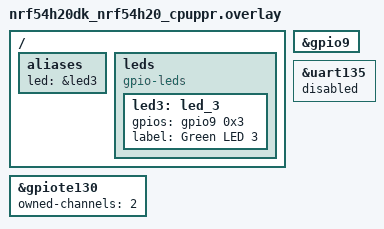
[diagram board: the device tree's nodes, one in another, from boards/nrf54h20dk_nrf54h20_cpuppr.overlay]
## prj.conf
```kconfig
CONFIG_GPIO=y

CONFIG_NCS_BOOT_BANNER=n
CONFIG_BOOT_BANNER=n
CONFIG_ASSERT=y

CONFIG_PRINTK=n
CONFIG_LOG=n
CONFIG_CONSOLE=n
CONFIG_UART_CONSOLE=n
CONFIG_SERIAL=n
```

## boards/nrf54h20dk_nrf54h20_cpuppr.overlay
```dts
/*
 * Copyright (c) 2026 Nordic Semiconductor ASA
 *
 * SPDX-License-Identifier: LicenseRef-Nordic-5-Clause
 */

/ {
	aliases {
		led = &led3;
	};

	leds {
		compatible = "gpio-leds";

		led3: led_3 {
			gpios = <&gpio9 0x3 0x0>;
			label = "Green LED 3";
		};
	};
};

&gpio9 {
	status = "okay";
};

&gpiote130 {
	status = "okay";
	owned-channels = <2>;
};

/* UART135 is owned by Radio core. */
&uart135 {
	status = "disabled";
};
```

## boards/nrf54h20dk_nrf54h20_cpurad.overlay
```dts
/*
 * Copyright (c) 2024 Nordic Semiconductor ASA
 *
 * SPDX-License-Identifier: LicenseRef-Nordic-5-Clause
 */

/ {
	aliases {
		led = &led1;
	};

	leds {
		compatible = "gpio-leds";

		led1: led_1 {
			gpios = <&gpio9 1 GPIO_ACTIVE_HIGH>;
			label = "Green LED 1";
		};
	};
};

&gpio9 {
	status = "okay";
};

&gpiote130 {
	status = "okay";
};
```

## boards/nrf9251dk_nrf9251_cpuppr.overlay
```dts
/*
 * Copyright (c) 2026 Nordic Semiconductor ASA
 *
 * SPDX-License-Identifier: LicenseRef-Nordic-5-Clause
 */

/ {
	aliases {
		led = &led1;
	};

	leds {
		compatible = "gpio-leds";

		/* Move to other GPIO. */
		led1: led_1 {
			gpios = <&gpio2 1 GPIO_ACTIVE_HIGH>;
			label = "Custom GPIO";
		};
	};
};

&gpio2 {
	status = "okay";
};

&gpiote130 {
	status = "okay";
};
```

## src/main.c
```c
/*
 * Copyright (c) 2024 Nordic Semiconductor ASA
 *
 * SPDX-License-Identifier: LicenseRef-Nordic-5-Clause
 */

#include <zephyr/kernel.h>

int main(void)
{

	k_msleep(2000);

	return 0;
}
```
